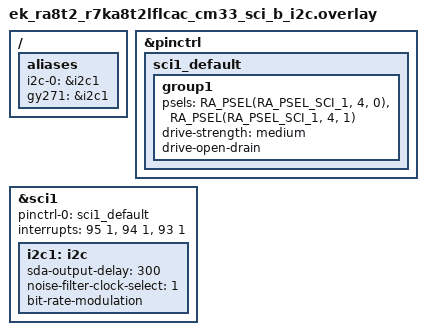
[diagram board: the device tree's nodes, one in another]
/*
 * Copyright (c) 2026 Renesas Electronics Corporation
 * SPDX-License-Identifier: Apache-2.0
 */

/ {
	aliases {
		i2c-0 = &i2c1;
		gy271 = &i2c1;
	};
};

&pinctrl {
	sci1_default: sci1_default {
		group1 {
			/* SDA1 SCL1*/
			psels = <RA_PSEL(RA_PSEL_SCI_1, 4, 0)>,
				<RA_PSEL(RA_PSEL_SCI_1, 4, 1)>;
			drive-strength = "medium";
			drive-open-drain;
		};
	};
};

&sci1 {
	pinctrl-0 = <&sci1_default>;
	pinctrl-names = "default";
	interrupts = <95 1>, <94 1>, <93 1>;
	interrupt-names = "rxi", "txi", "tei";
	status = "okay";

	i2c1: i2c {
		sda-output-delay = <300>;
		noise-filter-clock-select = <1>;
		bit-rate-modulation;
		status = "okay";
	};
};
